# Captivate_1 register map
Vendor: Texas Instruments
Peripheral module from a debugger description file (folder msp430).
Registers are 16-bit, read-write, reset 0x0 unless marked. A register's access mark holds for its fields unless they carry their own. Offsets are as the file gives them; lines under a group give offsets from that group; [hi:lo] are bit positions; {n}, {i} and the like mark numbered series; 'fields as' and 'values as' point back to an identical list; <NAME> marks a mode.

## Captivate
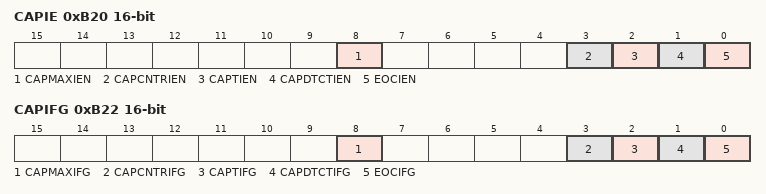
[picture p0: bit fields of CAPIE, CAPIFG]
0xB20 CAPIE — Captivate Interrupt Enable Register
  [8] CAPMAXIEN — Captivate maximum count interrupt enable
  [3] CAPCNTRIEN — Captivate Conversion Counter interrupt enable
  [2] CAPTIEN — Captivate Timer interrupt enable
  [1] CAPDTCTIEN — Captivate detection interrupt enable
  [0] EOCIEN — End of conversion interrupt enable
0xB22 CAPIFG — Captivate Interrupt Flag Register
  [8] CAPMAXIFG — Captivate maximum count interrupt flag
  [3] CAPCNTRIFG — Captivate Conversion Counter interrupt flag
  [2] CAPTIFG — Captivate Timer interrupt flag
  [1] CAPDTCTIFG — Captivate detection interrupt flag
  [0] EOCIFG — End of conversion interrupt flag
0xB24 CAPIV access not given reset not defined — Captivate Interrupt Vector Register
